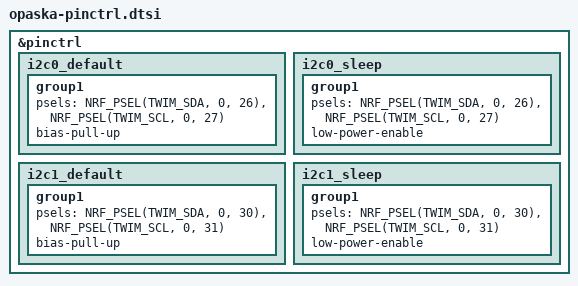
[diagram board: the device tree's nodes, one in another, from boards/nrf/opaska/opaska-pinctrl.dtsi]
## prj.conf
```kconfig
# Bluetooth (peripheral + GATT + notify)
CONFIG_BT=y
CONFIG_BT_PERIPHERAL=y
CONFIG_BT_DEVICE_NAME="nRF BPM"
CONFIG_BT_DEVICE_APPEARANCE=833
CONFIG_BT_MAX_PAIRED=1
CONFIG_BT_MAX_CONN=1
CONFIG_GPIO=y
CONFIG_GPIO_NRFX=y

CONFIG_BUILD_OUTPUT_HEX=y

# I2C (czujnik MAX30102)
CONFIG_I2C=y

# Wątek główny
CONFIG_MAIN_STACK_SIZE=4096
CONFIG_SYSTEM_WORKQUEUE_STACK_SIZE=2048

# Optymalizacja i debug
CONFIG_NEWLIB_LIBC=y
CONFIG_ASSERT=n
CONFIG_DEBUG_OPTIMIZATIONS=n
CONFIG_SPEED_OPTIMIZATIONS=y 
CONFIG_LOG=n
CONFIG_PRINTK=n
CONFIG_CONSOLE=n
CONFIG_UART_CONSOLE=n
CONFIG_SERIAL=n
CONFIG_BT_RX_STACK_SIZE=2048
CONFIG_BT_HCI_TX_STACK_SIZE=1024
CONFIG_HEAP_MEM_POOL_SIZE=4096

CONFIG_CLOCK_CONTROL=y
CONFIG_CLOCK_CONTROL_NRF=y

CONFIG_CLOCK_CONTROL_NRF_K32SRC_SYNTH=n
CONFIG_CLOCK_CONTROL_NRF_K32SRC_XTAL=y
CONFIG_CLOCK_CONTROL_NRF_K32SRC_RC=n

CONFIG_PM=y
CONFIG_PM_DEVICE=y
CONFIG_PM_DEVICE_RUNTIME=y
CONFIG_TICKLESS_KERNEL=y

# Preferowane parametry połączenia (jednostki: interval = 1.25 ms, timeout = 10 ms)
CONFIG_BT_PERIPHERAL_PREF_MIN_INT=160      
CONFIG_BT_PERIPHERAL_PREF_MAX_INT=320      

# W zależności od wersji Zephyra masz jedną z opcji:
CONFIG_BT_PERIPHERAL_PREF_LATENCY=4       
# albo:
# CONFIG_BT_PERIPHERAL_PREF_SLAVE_LATENCY=4

CONFIG_BT_PERIPHERAL_PREF_TIMEOUT=600     
```

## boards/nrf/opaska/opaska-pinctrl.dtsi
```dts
#include <zephyr/dt-bindings/pinctrl/nrf-pinctrl.h>

&pinctrl {
	i2c0_default: i2c0_default {
		group1 {
			psels = <NRF_PSEL(TWIM_SDA, 0, 26)>,
				<NRF_PSEL(TWIM_SCL, 0, 27)>;
			bias-pull-up;
		};
	};

	i2c0_sleep: i2c0_sleep {
		group1 {
			psels = <NRF_PSEL(TWIM_SDA, 0, 26)>,
				<NRF_PSEL(TWIM_SCL, 0, 27)>;
			low-power-enable;
		};
	};

	i2c1_default: i2c1_default {
		group1 {
			psels = <NRF_PSEL(TWIM_SDA, 0, 30)>,
				<NRF_PSEL(TWIM_SCL, 0, 31)>;
			bias-pull-up;
		};
	};

	i2c1_sleep: i2c1_sleep {
		group1 {
			psels = <NRF_PSEL(TWIM_SDA, 0, 30)>,
				<NRF_PSEL(TWIM_SCL, 0, 31)>;
			low-power-enable;
		};
	};
};
```

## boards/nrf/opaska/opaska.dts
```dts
/dts-v1/;

#include <nordic/nrf52840_qfaa.dtsi>
#include <nordic/nrf52840_partition.dtsi>
#include "opaska-pinctrl.dtsi"

&gpio0 { status = "okay"; };
&gpio1 { status = "okay"; };
&gpiote { status = "okay"; };

// &uart0 {
// 	status = "disabled";
// 	current-speed = <115200>;
// 	pinctrl-0 = <&uart0_default>;
// 	pinctrl-1 = <&uart0_sleep>;
// 	pinctrl-names = "default", "sleep";
// };

&i2c0 {
	status = "okay";
	pinctrl-0 = <&i2c0_default>;
	pinctrl-1 = <&i2c0_sleep>;
	pinctrl-names = "default", "sleep";
	clock-frequency = <I2C_BITRATE_STANDARD>;
};

&i2c1 {
	status = "okay";
	pinctrl-0 = <&i2c1_default>;
	pinctrl-1 = <&i2c1_sleep>;
	pinctrl-names = "default", "sleep";
	clock-frequency = <I2C_BITRATE_STANDARD>;
};

// &spi0 {
// 	status = "disabled";
// 	pinctrl-0 = <&spi0_default>;
// 	pinctrl-1 = <&spi0_sleep>;
// 	pinctrl-names = "default", "sleep";
// };
```

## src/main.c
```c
#include <zephyr/kernel.h>
#include <zephyr/drivers/i2c.h>
#include <zephyr/drivers/gpio.h>
#include <zephyr/device.h>
#include <zephyr/devicetree.h>
#include <stdint.h>
#include <stdbool.h>

#include "bpm.h"
#include "bpm_ble.h"
#include "wear_detect.h"

#define I2C_BPM_NODE   DT_NODELABEL(i2c0)
#define I2C_TEMP_NODE  DT_NODELABEL(i2c1)

#define BUZZER_PORT    DT_NODELABEL(gpio1)
#define BUZZER_PIN     15
#define TONE_HZ        4000

#define CALIBRATION_MS      15000
#define SEND_INTERVAL_MS     4000

#define BPM_MAX_VALID     200U
#define SPO2_MAX_VALID    100U

#define HR_ALARM_ON                 70U /* 70 bpm do testów*/
#define HR_ALARM_OFF                75U /* 75 bpm do testów*/
#define HR_ALARM_CONFIRM_SAMPLES    2U

#define ALARM_BEEP_PERIOD_MS        1000
#define ALARM_BEEP_TONE_MS          80

/* Timing */
#define MEAS_PERIOD_MS              40      /* 25 Hz */
#define WEAR_CHECK_ON_MS            1000
#define WEAR_CHECK_OFF_MS           200
#define OFF_BEEP_PERIOD_MS          1360

static const struct device *i2c_bpm;
static const struct device *i2c_temp;
static const struct device *buzzer_gpio;

/* generowanie dzwięku buzezera */
static void buzzer_tone(uint32_t freq_hz, uint32_t duration_ms)
{
    int64_t t_end = k_uptime_get() + (int64_t)duration_ms;
    uint32_t half_period_us = 1000000U / (freq_hz * 2U);

    while (k_uptime_get() < t_end) {
        gpio_pin_set(buzzer_gpio, BUZZER_PIN, 1);
        k_busy_wait(half_period_us);
        gpio_pin_set(buzzer_gpio, BUZZER_PIN, 0);
        k_busy_wait(half_period_us);
    }
    gpio_pin_set(buzzer_gpio, BUZZER_PIN, 0);
}
/* Ustawienie dźwięku dla opaski */
static void buzzer_band_off_pattern(void)
{
    buzzer_tone(TONE_HZ, 120);
    k_msleep(120);
    buzzer_tone(TONE_HZ, 120);
}
/* Ustawienie dźwięku dla alarmu opaski*/
static void buzzer_alarm_pattern(void)
{
    buzzer_tone(TONE_HZ, ALARM_BEEP_TONE_MS);
    k_msleep(ALARM_BEEP_TONE_MS);
    buzzer_tone(TONE_HZ, ALARM_BEEP_TONE_MS);
}
/* Sprawdzenie poprawności próbek */
static bool sample_valid(uint16_t hr, uint8_t s)
{
    if (hr == 0U || s == 0U) {
        return false;
    }
    if (hr > BPM_MAX_VALID) {
        return false;
    }
    if (s > SPO2_MAX_VALID) {
        return false;
    }
    return true;
}

static int64_t min_i64(int64_t a, int64_t b)
{
    return (a < b) ? a : b;
}

/* stan */
struct app_state {
    bool worn;
    bool calibrated;
    int64_t calib_end_ms;

    bool alarm_active;
    uint8_t low_confirm;
    uint8_t high_confirm;
    uint8_t last_alarm_sent;
};

static struct app_state st;
/* Ustawienie alarmu */
static void alarm_set(uint8_t on)
{
    on = on ? 1U : 0U;
    if (st.last_alarm_sent != on) {
        (void)ble_alarm_update(on);
        st.last_alarm_sent = on;
    }
}
/* Ustawienie dźwięku dla opaski */
static void on_band_put_on(int64_t now_ms)
{
    st.worn = true;
    st.calibrated = false;
    st.calib_end_ms = now_ms + (int64_t)CALIBRATION_MS;

    st.alarm_active = false;
    st.low_confirm = 0U;
    st.high_confirm = 0U;
    st.last_alarm_sent = 0U;

    alarm_set(0U);
    (void)ble_update(0U, 0U, true);
}
/* Ustawienie dźwięku dla opaski */
static void on_band_taken_off(void)
{
    st.worn = false;
    st.calibrated = false;

    st.alarm_active = false;
    st.low_confirm = 0U;
    st.high_confirm = 0U;
    st.last_alarm_sent = 0U;

    alarm_set(0U);
    (void)ble_update(0U, 0U, false);
}

int main(void)
{
    i2c_bpm  = DEVICE_DT_GET(I2C_BPM_NODE);
    i2c_temp = DEVICE_DT_GET(I2C_TEMP_NODE);
    buzzer_gpio = DEVICE_DT_GET(BUZZER_PORT);

    if (!device_is_ready(i2c_bpm) || !device_is_ready(i2c_temp)) {
        return 0;
    }
    if (!device_is_ready(buzzer_gpio)) {
        return 0;
    }
    if (gpio_pin_configure(buzzer_gpio, BUZZER_PIN, GPIO_OUTPUT_INACTIVE) != 0) {
        return 0;
    }

    bpm_init(i2c_bpm);
    (void)wear_detect_init(i2c_temp);
    ble_init();

    st.worn = false;
    st.calibrated = false;
    st.alarm_active = false;
    st.low_confirm = 0U;
    st.high_confirm = 0U;
    st.last_alarm_sent = 0U;
    st.calib_end_ms = 0;

    int64_t now = k_uptime_get();

    int64_t next_meas_ms       = now + (int64_t)MEAS_PERIOD_MS;
    int64_t next_wear_ms       = now;
    int64_t next_send_ms       = now + (int64_t)SEND_INTERVAL_MS;
    int64_t next_alarm_beep_ms = now + (int64_t)ALARM_BEEP_PERIOD_MS;
    int64_t next_off_beep_ms   = now;

    /* Wykryj czy założona */
    bool worn0 = wear_detect(i2c_temp);
    now = k_uptime_get();
    if (worn0) {
        on_band_put_on(now);
        next_send_ms = st.calib_end_ms;
        next_wear_ms = now + (int64_t)WEAR_CHECK_ON_MS;
    } else {
        on_band_taken_off();
        next_wear_ms = now + (int64_t)WEAR_CHECK_OFF_MS;
    }

    while (1) {
        now = k_uptime_get();

        /* Wear detect */
        if (now >= next_wear_ms) {
            bool w = wear_detect(i2c_temp);

            if (w && !st.worn) {
                on_band_put_on(now);
                next_send_ms = st.calib_end_ms;
                next_meas_ms = now + (int64_t)MEAS_PERIOD_MS;
                next_wear_ms = now + (int64_t)WEAR_CHECK_ON_MS;
            } else if (!w && st.worn) {
                on_band_taken_off();
                next_off_beep_ms = now;
                next_wear_ms = now + (int64_t)WEAR_CHECK_OFF_MS;
            } else {
                next_wear_ms = now + (int64_t)(st.worn ? WEAR_CHECK_ON_MS : WEAR_CHECK_OFF_MS);
            }
        }

        if (st.worn) {
            /* Kalibracja */
            if (!st.calibrated && now >= st.calib_end_ms) {
                st.calibrated = true;
                st.alarm_active = false;
                st.low_confirm = 0U;
                st.high_confirm = 0U;
                alarm_set(0U);
                next_send_ms = now;
            }

            /* nadrabiaj brakujące ticki  */
            int catchup = 0;
            while (now >= next_meas_ms && catchup < 5) {
                bpm_process(i2c_bpm);
                next_meas_ms += (int64_t)MEAS_PERIOD_MS;
                catchup++;
                now = k_uptime_get();
            }
            if (catchup >= 5) {
                /* jak było duże opóźnienie, zresync do "teraz" */
                next_meas_ms = now + (int64_t)MEAS_PERIOD_MS;
            }

            /* Logika alarmu po aktualizacji bpm/spo2 */
            if (st.calibrated && sample_valid(bpm, spo2)) {
                if (!st.alarm_active) {
                    if (bpm < HR_ALARM_ON) {
                        if (st.low_confirm < 255U) {
                            st.low_confirm++;
                        }
                        if (st.low_confirm >= HR_ALARM_CONFIRM_SAMPLES) {
                            st.alarm_active = true;
                            st.high_confirm = 0U;
                            alarm_set(1U);
                            next_alarm_beep_ms = now;
                        }
                    } else {
                        st.low_confirm = 0U;
                    }
                } else {
                    if (bpm > HR_ALARM_OFF) {
                        if (st.high_confirm < 255U) {
                            st.high_confirm++;
                        }
                        if (st.high_confirm >= HR_ALARM_CONFIRM_SAMPLES) {
                            st.alarm_active = false;
                            st.low_confirm = 0U;
                            alarm_set(0U);
                        }
                    } else {
                        st.high_confirm = 0U;
                    }
                }
            }

            /* Alarm beep */
            if (st.calibrated && st.alarm_active && now >= next_alarm_beep_ms) {
                buzzer_alarm_pattern();
                next_alarm_beep_ms += (int64_t)ALARM_BEEP_PERIOD_MS;
                while (next_alarm_beep_ms <= now) {
                    next_alarm_beep_ms += (int64_t)ALARM_BEEP_PERIOD_MS;
                }
            }

            /* BLE wysyłka */
            if (st.calibrated && now >= next_send_ms) {
                if (sample_valid(bpm, spo2)) {
                    (void)ble_update(bpm, spo2, true);
                } else {
                    (void)ble_update(0U, 0U, true);
                }

                next_send_ms += (int64_t)SEND_INTERVAL_MS;
                while (next_send_ms <= now) {
                    next_send_ms += (int64_t)SEND_INTERVAL_MS;
                }
            }
        } else {
            /* Zdjęta */
            if (now >= next_off_beep_ms) {
                buzzer_band_off_pattern();
                next_off_beep_ms = now + (int64_t)OFF_BEEP_PERIOD_MS;
            }
        }

        /* Sen do najbli ższego deadline */
        int64_t next_deadline = now + 50;
        next_deadline = min_i64(next_deadline, next_wear_ms);

        if (st.worn) {
            next_deadline = min_i64(next_deadline, next_meas_ms);
            if (st.calibrated) {
                next_deadline = min_i64(next_deadline, next_send_ms);
                if (st.alarm_active) {
                    next_deadline = min_i64(next_deadline, next_alarm_beep_ms);
                }
            }
        } else {
            next_deadline = min_i64(next_deadline, next_off_beep_ms);
        }

        int64_t sleep_ms = next_deadline - k_uptime_get();
        if (sleep_ms < 0) {
            sleep_ms = 0;
        }
        if (sleep_ms > 100) {
            sleep_ms = 100;
        }

        k_msleep((uint32_t)sleep_ms);
    }

    return 0;
}
```

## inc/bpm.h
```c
#ifndef BPM_H_
#define BPM_H_

#include <zephyr/device.h>
#include <stdint.h>

/* Wyniki ostatniego poprawnego pomiaru */
extern uint16_t bpm;  
extern uint8_t  spo2; 

void bpm_init(const struct device *i2c_dev);
void bpm_process(const struct device *i2c_dev);
void bpm_reset_state(void);

#endif 
```

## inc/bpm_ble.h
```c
#pragma once
#include <stdint.h>
#include <stdbool.h>
void ble_init(void);

int ble_update(uint16_t bpm, uint8_t spo2, bool worn);

/* 0 = brak alarmu, 1 = alarm aktywny */
int ble_alarm_update(uint8_t alarm);
```

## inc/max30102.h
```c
#ifndef MAX30102_H_
#define MAX30102_H_

#include <zephyr/device.h>
#include <stdint.h>
#include <stdbool.h>

#define MAX30102_ADDRESS  0x57 // I2C Address for MAX30102

#define MAX30102_INT_STATUS_1        0x00
#define MAX30102_INT_STATUS_2        0x01
#define MAX30102_INT_ENABLE_1        0x02
#define MAX30102_INT_ENABLE_2        0x03
#define MAX30102_FIFO_WRITE_PTR      0x04
#define MAX30102_OVERFLOW_COUNT      0x05
#define MAX30102_FIFO_READ_PTR       0x06
#define MAX30102_REG_FIFO_DATA       0x07
#define MAX30102_FIFO_CONFIG         0x08
#define MAX30102_MODE_CONFIG         0x09
#define MAX30102_SPO2_CONFIG         0x0A
#define MAX30102_LED1_PULSE_AMP      0x0C
#define MAX30102_LED2_PULSE_AMP      0x0D
#define MAX30102_PARTID              0xFF
#define MAX30102_RESET               0x40

/* Deklaracje funkcji dostępnych globalnie */
int  MAX30102_check(const struct device *dev_i2c);
int  MAX30102_reset(const struct device *dev_i2c);
int  MAX30102_clear(const struct device *dev_i2c);
int  MAX30102_config(const struct device *dev_i2c);
bool MAX30102_read_fifo(const struct device *dev_i2c, uint32_t *pun_red_led, uint32_t *pun_ir_led);
bool MAX30102_read_reg(const struct device *dev_i2c, uint8_t uch_addr, uint8_t *puch_data);
bool MAX30102_set_shutdown(const struct device *i2c, bool en);
void max30102_enable(const struct device *dev, bool enable);
void max30102_read_samples(const struct device *dev);
uint8_t max30102_calculate_bpm(void);

#endif 
```

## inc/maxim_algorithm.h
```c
#ifndef MAXIM_ALGORITHM_H_
#define MAXIM_ALGORITHM_H_

#include <stdint.h>

void maxim_heart_rate_and_oxygen_saturation(
    uint32_t *ir_buf,
    int32_t buf_len,
    uint32_t *red_buf,
    int32_t *spo2,
    int8_t *spo2_valid,
    int32_t *heart_rate,
    int8_t *hr_valid);

#endif /* MAXIM_ALGORITHM_H_ */
```

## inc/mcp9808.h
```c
#pragma once
#include <zephyr/device.h>
#include <stdbool.h>
// Odczyt temperatury z MCP9808
bool mcp9808_read_temp(const struct device *i2c, float *out_temp_c);
```

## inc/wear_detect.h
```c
#pragma once
#include <zephyr/device.h>
#include <stdbool.h>

// Inicjalizacja czujnika temperatury
bool wear_detect_init(const struct device *i2c_temp);
// Wykrywanie czy urządzenie jest założone
bool wear_detect(const struct device *i2c_temp);
```

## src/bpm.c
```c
#include "bpm.h"
#include "max30102.h"
#include "maxim_algorithm.h"
#include <zephyr/kernel.h>
#include <stdint.h>
#include <stdbool.h>

#define MAXIM_BUF_LEN   100     /* 4 sekundy przy FreqS=25 w algorytmie */
#define FILTER_SIZE     5

static int bpm_buffer[FILTER_SIZE];
static int bpm_index = 0;
static bool buffer_filled = false;

static uint32_t ir_buf[MAXIM_BUF_LEN];
static uint32_t red_buf[MAXIM_BUF_LEN];
static int buf_idx = 0;


uint16_t bpm = 0;
uint8_t  spo2 = 0;

/* Ostatnie poprawne wyniki */
static uint16_t last_bpm = 0;
static uint8_t  last_spo2 = 0;

static int bpm_get_filtered(int new_bpm)
{
    bpm_buffer[bpm_index++] = new_bpm;
    if (bpm_index >= FILTER_SIZE) {
        bpm_index = 0;
        buffer_filled = true;
    }

    int count = buffer_filled ? FILTER_SIZE : bpm_index;
    int sum = 0;
    for (int i = 0; i < count; i++) {
        sum += bpm_buffer[i];
    }
    return (count > 0) ? (sum / count) : new_bpm;
}
    /* Inicjalizacja modułu BPM */
void bpm_init(const struct device *i2c_dev)
{
    MAX30102_check(i2c_dev);
    MAX30102_reset(i2c_dev);
    k_msleep(100);

    MAX30102_config(i2c_dev);
    k_msleep(100);

    buf_idx = 0;
    bpm = 0;
    spo2 = 0;
    last_bpm = 0;
    last_spo2 = 0;
    bpm_index = 0;
    buffer_filled = false;
}
/* Przetwarzanie danych BPM */
void bpm_process(const struct device *i2c_dev)
{
    uint32_t ir_raw = 0, red_raw = 0;

    if (!MAX30102_read_fifo(i2c_dev, &red_raw, &ir_raw)) {
        return;
    }

    ir_buf[buf_idx]  = ir_raw;
    red_buf[buf_idx] = red_raw;
    buf_idx++;

    if (buf_idx >= MAXIM_BUF_LEN) {
        int32_t spo2_calc = 0, hr_calc = 0;
        int8_t spo2_valid = 0, hr_valid = 0;

        maxim_heart_rate_and_oxygen_saturation(
            ir_buf, MAXIM_BUF_LEN, red_buf,
            &spo2_calc, &spo2_valid, &hr_calc, &hr_valid);

        if (hr_valid) {
            int32_t hr = hr_calc;
            if (hr < 0) { hr = 0; }
            if (hr > 250) { hr = 250; }
            last_bpm = (uint16_t)bpm_get_filtered((int)hr);
        }

        if (spo2_valid) {
            int32_t s = spo2_calc;
            if (s < 0) { s = 0; }
            if (s > 100) { s = 100; }
            last_spo2 = (uint8_t)s;
        }

        bpm = last_bpm;
        spo2 = last_spo2;

        buf_idx = 0;
    }
}
/* Resetowanie stanu modułu BPM */
void bpm_reset_state(void)
{
    /* reset filtra */
    for (int i = 0; i < FILTER_SIZE; i++) {
        bpm_buffer[i] = 0;
    }
    bpm_index = 0;
    buffer_filled = false;

    /* reset buforów próbek */
    for (int i = 0; i < MAXIM_BUF_LEN; i++) {
        ir_buf[i] = 0;
        red_buf[i] = 0;
    }
    buf_idx = 0;

    /* reset wyników */
    bpm = 0;
    spo2 = 0;
    last_bpm = 0;
    last_spo2 = 0;
}
```

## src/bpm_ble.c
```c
#include <zephyr/kernel.h>
#include <zephyr/sys/byteorder.h>
#include <zephyr/sys/util.h>
#include <errno.h>
#include <stdbool.h>
#include <stdint.h>

#include <zephyr/bluetooth/bluetooth.h>
#include <zephyr/bluetooth/conn.h>
#include <zephyr/bluetooth/gatt.h>
#include <zephyr/bluetooth/hci.h>

#include "bpm_ble.h"

/* HR (0x180D/0x2A37) */
static struct bt_uuid_16 hrs_uuid = BT_UUID_INIT_16(0x180D);
static struct bt_uuid_16 hrm_uuid = BT_UUID_INIT_16(0x2A37);

static bool hrm_notify_enabled;
static uint8_t hrm_payload[2];

static void hrm_ccc_cfg_changed(const struct bt_gatt_attr *attr, uint16_t value)
{
    ARG_UNUSED(attr);
    hrm_notify_enabled = (value == BT_GATT_CCC_NOTIFY);
}

BT_GATT_SERVICE_DEFINE(hrs_svc,
    BT_GATT_PRIMARY_SERVICE(&hrs_uuid.uuid),
    BT_GATT_CHARACTERISTIC(&hrm_uuid.uuid,
        BT_GATT_CHRC_NOTIFY,
        BT_GATT_PERM_NONE,
        NULL, NULL, hrm_payload),
    BT_GATT_CCC(hrm_ccc_cfg_changed, BT_GATT_PERM_READ | BT_GATT_PERM_WRITE)
);

static int hrs_notify(struct bt_conn *conn, uint16_t bpm, bool worn)
{
    if (!conn || !hrm_notify_enabled) {
        return 0;
    }

    hrm_payload[0] = 0x00;
    hrm_payload[0] |= (1U << 1);
    if (worn) {
        hrm_payload[0] |= (1U << 2);
    }
    hrm_payload[1] = (uint8_t)MIN(bpm, 255);

    return bt_gatt_notify(conn, &hrs_svc.attrs[2], hrm_payload, sizeof(hrm_payload));
}

/* PLX (0x1822/0x2A5F + 0x2A60) */
static struct bt_uuid_16 plx_svc_uuid  = BT_UUID_INIT_16(0x1822);
static struct bt_uuid_16 plx_cont_uuid = BT_UUID_INIT_16(0x2A5F);
static struct bt_uuid_16 plx_feat_uuid = BT_UUID_INIT_16(0x2A60);

static bool plx_notify_enabled;
static uint8_t plx_payload[5];
static uint16_t plx_features_le = 0x0000;

static void plx_ccc_cfg_changed(const struct bt_gatt_attr *attr, uint16_t value)
{
    ARG_UNUSED(attr);
    plx_notify_enabled = (value == BT_GATT_CCC_NOTIFY);
}

static ssize_t read_plx_features(struct bt_conn *conn,
                                 const struct bt_gatt_attr *attr,
                                 void *buf, uint16_t len, uint16_t offset)
{
    ARG_UNUSED(attr);
    return bt_gatt_attr_read(conn, attr, buf, len, offset,
                             &plx_features_le, sizeof(plx_features_le));
}

static uint16_t sfloat_encode_int(int16_t mantissa, int8_t exponent)
{
    uint16_t m = (uint16_t)mantissa & 0x0FFF;
    uint16_t e = ((uint16_t)exponent & 0x000F) << 12;
    return (uint16_t)(e | m);
}

BT_GATT_SERVICE_DEFINE(plx_svc,
    BT_GATT_PRIMARY_SERVICE(&plx_svc_uuid.uuid),

    BT_GATT_CHARACTERISTIC(&plx_cont_uuid.uuid,
        BT_GATT_CHRC_NOTIFY,
        BT_GATT_PERM_NONE,
        NULL, NULL, plx_payload),
    BT_GATT_CCC(plx_ccc_cfg_changed, BT_GATT_PERM_READ | BT_GATT_PERM_WRITE),

    BT_GATT_CHARACTERISTIC(&plx_feat_uuid.uuid,
        BT_GATT_CHRC_READ,
        BT_GATT_PERM_READ,
        read_plx_features, NULL, &plx_features_le)
);

static int plx_notify(struct bt_conn *conn, uint8_t spo2_percent, uint16_t pulse_rate_bpm)
{
    if (!conn || !plx_notify_enabled) {
        return 0;
    }

    plx_payload[0] = 0x00;

    uint16_t spo2_sf = sfloat_encode_int((int16_t)spo2_percent, 0);
    uint16_t pr_sf   = sfloat_encode_int((int16_t)MIN(pulse_rate_bpm, 300), 0);

    sys_put_le16(spo2_sf, &plx_payload[1]);
    sys_put_le16(pr_sf,   &plx_payload[3]);

    return bt_gatt_notify(conn, &plx_svc.attrs[2], plx_payload, sizeof(plx_payload));
}

/* Custom */
#define BT_UUID_BPM_SPO2_SVC_VAL \
    BT_UUID_128_ENCODE(0x12345678, 0x1234, 0x5678, 0x1234, 0x56789abcdef0)

#define BT_UUID_SPO2_CHAR_VAL \
    BT_UUID_128_ENCODE(0x1234567a, 0x1234, 0x5678, 0x1234, 0x56789abcdef0)

#define BT_UUID_ALARM_CHAR_VAL \
    BT_UUID_128_ENCODE(0x1234567b, 0x1234, 0x5678, 0x1234, 0x56789abcdef0)

static struct bt_uuid_128 custom_svc_uuid = BT_UUID_INIT_128(BT_UUID_BPM_SPO2_SVC_VAL);
static struct bt_uuid_128 spo2_uuid       = BT_UUID_INIT_128(BT_UUID_SPO2_CHAR_VAL);
static struct bt_uuid_128 alarm_uuid      = BT_UUID_INIT_128(BT_UUID_ALARM_CHAR_VAL);

static uint8_t g_spo2;
static uint8_t g_alarm;

static bool spo2_notify_enabled;
static bool alarm_notify_enabled;

static void spo2_ccc_cfg_changed(const struct bt_gatt_attr *attr, uint16_t value)
{
    ARG_UNUSED(attr);
    spo2_notify_enabled = (value == BT_GATT_CCC_NOTIFY);
}

static void alarm_ccc_cfg_changed(const struct bt_gatt_attr *attr, uint16_t value)
{
    ARG_UNUSED(attr);
    alarm_notify_enabled = (value == BT_GATT_CCC_NOTIFY);
}

BT_GATT_SERVICE_DEFINE(custom_svc,
    BT_GATT_PRIMARY_SERVICE(&custom_svc_uuid),

    BT_GATT_CHARACTERISTIC(&spo2_uuid.uuid,
        BT_GATT_CHRC_NOTIFY,
        BT_GATT_PERM_NONE,
        NULL, NULL, &g_spo2),
    BT_GATT_CCC(spo2_ccc_cfg_changed, BT_GATT_PERM_READ | BT_GATT_PERM_WRITE),

    BT_GATT_CHARACTERISTIC(&alarm_uuid.uuid,
        BT_GATT_CHRC_NOTIFY,
        BT_GATT_PERM_NONE,
        NULL, NULL, &g_alarm),
    BT_GATT_CCC(alarm_ccc_cfg_changed, BT_GATT_PERM_READ | BT_GATT_PERM_WRITE)
);

/* Adv + conn */
static struct bt_conn *current_conn;

static const struct bt_data ad[] = {
    BT_DATA_BYTES(BT_DATA_FLAGS, (BT_LE_AD_GENERAL | BT_LE_AD_NO_BREDR)),
    BT_DATA_BYTES(BT_DATA_UUID16_ALL, 0x0D, 0x18, 0x22, 0x18),
    BT_DATA_BYTES(BT_DATA_UUID128_ALL, BT_UUID_BPM_SPO2_SVC_VAL),
};

static const struct bt_data sd[] = {
    BT_DATA(BT_DATA_NAME_COMPLETE, CONFIG_BT_DEVICE_NAME,
            sizeof(CONFIG_BT_DEVICE_NAME) - 1),
};

static const struct bt_le_adv_param adv_param = {
    .id = BT_ID_DEFAULT,
    .options = BT_LE_ADV_OPT_CONN,
    .interval_min = 0x0640,
    .interval_max = 0x06A4,
    .peer = NULL,
};

static int start_advertising(void)
{
    int err = bt_le_adv_start(&adv_param, ad, ARRAY_SIZE(ad), sd, ARRAY_SIZE(sd));
    if (err == -EALREADY) {
        return 0;
    }
    return err;
}

static void adv_work_handler(struct k_work *work);
K_WORK_DELAYABLE_DEFINE(adv_work, adv_work_handler);

static void adv_work_handler(struct k_work *work)
{
    ARG_UNUSED(work);
    (void)start_advertising();
}

static void connected(struct bt_conn *conn, uint8_t err)
{
    if (err) {
        return;
    }

    if (current_conn) {
        bt_conn_unref(current_conn);
    }
    current_conn = bt_conn_ref(conn);
}

static void disconnected(struct bt_conn *conn, uint8_t reason)
{
    ARG_UNUSED(conn);
    ARG_UNUSED(reason);

    hrm_notify_enabled = false;
    plx_notify_enabled = false;
    spo2_notify_enabled = false;
    alarm_notify_enabled = false;

    if (current_conn) {
        bt_conn_unref(current_conn);
        current_conn = NULL;
    }

    (void)k_work_schedule(&adv_work, K_MSEC(200));
}

BT_CONN_CB_DEFINE(conn_cb) = {
    .connected = connected,
    .disconnected = disconnected,
};

void ble_init(void)
{
    int err = bt_enable(NULL);
    if (err) {
        return;
    }

    g_spo2 = 0;
    g_alarm = 0;

    plx_features_le = sys_cpu_to_le16(plx_features_le);

    (void)start_advertising();
}

int ble_update(uint16_t bpm, uint8_t spo2, bool worn)
{
    int err;

    g_spo2 = spo2;

    if (!current_conn) {
        return 0;
    }

    err = hrs_notify(current_conn, bpm, worn);
    if (err == -ENOMEM || err == -EAGAIN) {
        err = 0;
    }
    if (err) {
        return err;
    }

    err = plx_notify(current_conn, spo2, bpm);
    if (err == -ENOMEM || err == -EAGAIN) {
        err = 0;
    }
    if (err) {
        return err;
    }

    if (spo2_notify_enabled) {
        err = bt_gatt_notify_uuid(current_conn, &spo2_uuid.uuid,
                                  custom_svc.attrs, &g_spo2, sizeof(g_spo2));
        if (err == -ENOMEM || err == -EAGAIN) {
            err = 0;
        }
        if (err) {
            return err;
        }
    }

    return 0;
}

int ble_alarm_update(uint8_t alarm)
{
    int err;

    alarm = alarm ? 1U : 0U;
    if (g_alarm == alarm) {
        return 0;
    }

    g_alarm = alarm;

    if (!current_conn || !alarm_notify_enabled) {
        return 0;
    }

    err = bt_gatt_notify_uuid(current_conn, &alarm_uuid.uuid,
                              custom_svc.attrs, &g_alarm, sizeof(g_alarm));
    if (err == -ENOMEM || err == -EAGAIN) {
        return 0;
    }

    return err;
}
```

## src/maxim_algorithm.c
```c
/** \file maxim_algorithm.c ***************************************************
*
* Project: MAXREFDES117# (adaptacja)
* Filename: maxim_algorithm.c
* Description: This module calculates the heart rate/SpO2 level
*              (adapted for Zephyr / nRF52 environment)
*
* --------------------------------------------------------------------
*
* This code follows the following naming conventions:
*
* char              ch_pmod_value
* char (array)      s_pmod_s_string[16]
* float             f_pmod_value
* int32_t           n_pmod_value
* int32_t (array)   an_pmod_value[16]
* int16_t           w_pmod_value
* int16_t (array)   aw_pmod_value[16]
* uint16_t          uw_pmod_value
* uint16_t (array)  auw_pmod_value[16]
* uint8_t           uch_pmod_value
* uint8_t (array)   auch_pmod_buffer[16]
* uint32_t          un_pmod_value
* int32_t *         pn_pmod_value
*
* ------------------------------------------------------------------------- */
/*******************************************************************************
* Copyright (C) 2016 Maxim Integrated Products, Inc., All Rights Reserved.
*
* Permission is hereby granted, free of charge, to any person obtaining a
* copy of this software and associated documentation files (the "Software"),
* to deal in the Software without restriction, including without limitation
* the rights to use, copy, modify, merge, publish, distribute, sublicense,
* and/or sell copies of the Software, and to permit persons to whom the
* Software is furnished to do so, subject to the following conditions:
*
* The above copyright notice and this permission notice shall be included
* in all copies or substantial portions of the Software.
*
* THE SOFTWARE IS PROVIDED "AS IS", WITHOUT WARRANTY OF ANY KIND, EXPRESS
* OR IMPLIED, INCLUDING BUT NOT LIMITED TO THE WARRANTIES OF
* MERCHANTABILITY, FITNESS FOR A PARTICULAR PURPOSE AND NONINFRINGEMENT.
* IN NO EVENT SHALL MAXIM INTEGRATED BE LIABLE FOR ANY CLAIM, DAMAGES
* OR OTHER LIABILITY, WHETHER IN AN ACTION OF CONTRACT, TORT OR OTHERWISE,
* ARISING FROM, OUT OF OR IN CONNECTION WITH THE SOFTWARE OR THE USE OR
* OTHER DEALINGS IN THE SOFTWARE.
*
* Except as contained in this notice, the name of Maxim Integrated
* Products, Inc. shall not be used except as stated in the Maxim Integrated
* Products, Inc. Branding Policy.
*
* The mere transfer of this software does not imply any licenses
* of trade secrets, proprietary technology, copyrights, patents,
* trademarks, maskwork rights, or any other form of intellectual
* property whatsoever. Maxim Integrated Products, Inc. retains all
* ownership rights.
*******************************************************************************
*/

#include "maxim_algorithm.h"
#include <stdint.h>

#define FreqS 25
#define BUFFER_SIZE (FreqS * 4)   /* 100 próbek */
#define MA4_SIZE 4
#define min(x,y) ((x) < (y) ? (x) : (y))

/* Ustawienia pod nadgarstek */
#define HR_MAX_BPM       180      /* do min_dist w 1. przebiegu (bezpieczne) */
#define MIN_DIST_FRAC_N  6        /* 2. przebieg: min_dist ~= 0.7 * okresu */
#define MIN_DIST_FRAC_D  10

static const uint8_t uch_spo2_table[184] = {
    95,95,95,96,96,96,97,97,97,97,97,98,98,98,98,98,99,99,99,99,
    99,99,99,99,100,100,100,100,100,100,100,100,100,100,100,100,100,100,100,100,
    100,100,100,100,99,99,99,99,99,99,99,99,98,98,98,98,98,98,97,97,
    97,97,96,96,96,96,95,95,95,94,94,94,93,93,93,92,92,92,91,91,
    90,90,89,89,89,88,88,87,87,86,86,85,85,84,84,83,82,82,81,81,
    80,80,79,78,78,77,76,76,75,74,74,73,72,72,71,70,69,69,68,67,
    66,66,65,64,63,62,62,61,60,59,58,57,56,56,55,54,53,52,51,50,
    49,48,47,46,45,44,43,42,41,40,39,38,37,36,35,34,33,31,30,29,
    28,27,26,25,23,22,21,20,19,17,16,15,14,12,11,10,9,7,6,5,
    3,2,1
};

static int32_t an_x[BUFFER_SIZE]; /* IR */
static int32_t an_y[BUFFER_SIZE]; /* RED */

/**
* \brief        Sort array
* \par          Details
*               Sort array in ascending order (insertion sort algorithm)
*
* \retval       None
*/
static void maxim_sort_ascend(int32_t *x, int32_t n)
{
    for (int i = 1; i < n; i++) {
        int32_t t = x[i], j = i;
        while (j > 0 && t < x[j - 1]) {
            x[j] = x[j - 1];
            j--;
        }
        x[j] = t;
    }
}

/**
* \brief        Sort indices
* \par          Details
*               Sort indices according to descending order (insertion sort algorithm)
*
* \retval       None
*/
static void maxim_sort_indices_descend(int32_t *x, int32_t *idx, int32_t n)
{
    for (int i = 1; i < n; i++) {
        int32_t t = idx[i], j = i;
        while (j > 0 && x[t] > x[idx[j - 1]]) {
            idx[j] = idx[j - 1];
            j--;
        }
        idx[j] = t;
    }
}

/**
* \brief        Find peaks above n_min_height
* \par          Details
*               Find all peaks above MIN_HEIGHT
*
* \retval       None
*/
static void maxim_peaks_above_min_height(int32_t *locs, int32_t *npks,
                                         int32_t *x, int32_t n, int32_t min_h)
{
    *npks = 0;
    int32_t i = 1;

    while (i < n - 1) {
        if (x[i] > min_h && x[i] > x[i - 1]) {
            int32_t w = 1;
            while ((i + w) < n && x[i] == x[i + w]) {
                w++;
            }
            /* guard: i+w może == n */
            if ((i + w) < n && x[i] > x[i + w] && *npks < 15) {
                locs[(*npks)++] = i;
                i += (w + 1);
            } else {
                i += w;
            }
        } else {
            i++;
        }
    }
}

/**
* \brief        Remove peaks
* \par          Details
*               Remove peaks separated by less than MIN_DISTANCE
*
* \retval       None
*/
static void maxim_remove_close_peaks(int32_t *locs, int32_t *npks,
                                     int32_t *x, int32_t min_dist)
{
    int old_npks;
    maxim_sort_indices_descend(x, locs, *npks);

    for (int i = -1; i < *npks; i++) {
        old_npks = *npks;
        *npks = i + 1;

        for (int j = i + 1; j < old_npks; j++) {
            int d = locs[j] - (i == -1 ? -1 : locs[i]);
            if (d > min_dist || d < -min_dist) {
                locs[(*npks)++] = locs[j];
            }
        }
    }
    maxim_sort_ascend(locs, *npks);
}

/**
* \brief        Find peaks
* \par          Details
*               Find at most MAX_NUM peaks above MIN_HEIGHT separated by at least MIN_DISTANCE
*
* \retval       None
*/
static void maxim_find_peaks(int32_t *locs, int32_t *npks, int32_t *x, int32_t n,
                             int32_t min_h, int32_t min_dist, int32_t max_num)
{
    maxim_peaks_above_min_height(locs, npks, x, n, min_h);
    maxim_remove_close_peaks(locs, npks, x, min_dist);
    *npks = min(*npks, max_num);
}

/**
* \brief        Compute heart rate from median peak intervals
* \par          Details
*               Uses median of successive peak-to-peak distances (in samples),
*               then converts to BPM using sampling rate FreqS.
*
* \retval       Heart rate in BPM, or -999 on failure
*/
static int32_t hr_from_median_intervals(const int32_t *locs, int32_t npks)
{
    if (npks < 2) {
        return -999;
    }

    int32_t d[14];
    int32_t m = 0;

    for (int32_t k = 1; k < npks; k++) {
        d[m++] = (locs[k] - locs[k - 1]);
        if (m >= (int32_t)(sizeof(d) / sizeof(d[0]))) {
            break;
        }
    }

    if (m < 1) {
        return -999;
    }

    maxim_sort_ascend(d, m);
    int32_t med = (m % 2) ? d[m / 2] : (d[m / 2 - 1] + d[m / 2]) / 2;
    if (med <= 0) {
        return -999;
    }

    return (int32_t)((FreqS * 60) / med);
}

/**
* \brief        Calculate the heart rate and SpO2 level
* \par          Details
*               By detecting peaks (valleys after inversion) of PPG cycle and corresponding AC/DC
*               of red/infra-red signal, the ratio for the SPO2 is computed and mapped through a LUT.
*
* \param[in]    *ir_buf               - IR sensor data buffer
* \param[in]    n                    - IR/RED buffer length (expected BUFFER_SIZE)
* \param[in]    *red_buf              - Red sensor data buffer
* \param[out]   *spo2                 - Calculated SpO2 value
* \param[out]   *spo2_valid           - 1 if the calculated SpO2 value is valid
* \param[out]   *hr                   - Calculated heart rate value
* \param[out]   *hr_valid             - 1 if the calculated heart rate value is valid
*
* \retval       None
*/
void maxim_heart_rate_and_oxygen_saturation(
    uint32_t *ir_buf, int32_t n, uint32_t *red_buf,
    int32_t *spo2, int8_t *spo2_valid, int32_t *hr, int8_t *hr_valid)
{
    /* Zakładamy, że i tak wołasz z n==BUFFER_SIZE */
    (void)n;

    /* --- IR mean --- */
    uint32_t ir_mean = 0;
    for (int k = 0; k < BUFFER_SIZE; k++) {
        ir_mean += ir_buf[k];
    }
    ir_mean /= BUFFER_SIZE;

    /* remove DC and invert signal so that we can use peak detector as valley detector */
    for (int k = 0; k < BUFFER_SIZE; k++) {
        an_x[k] = -(int32_t)(ir_buf[k] - ir_mean);
    }

    /* 4 pt Moving Average */
    for (int k = 0; k < BUFFER_SIZE - MA4_SIZE; k++) {
        an_x[k] = (an_x[k] + an_x[k + 1] + an_x[k + 2] + an_x[k + 3]) / 4;
    }

    /* calculate threshold */
    int32_t th = 0;
    for (int k = 0; k < BUFFER_SIZE; k++) {
        th += an_x[k];
    }
    th /= BUFFER_SIZE;

    if (th < 30) th = 30;
    if (th > 60) th = 60;

    int32_t valley_locs[15] = {0};
    int32_t npks = 0;

    /* --- Pass 1: loose min_dist (based on HR_MAX_BPM) --- */
    int32_t min_dist1 = (FreqS * 60) / HR_MAX_BPM;
    if (min_dist1 < 4) min_dist1 = 4;

    maxim_find_peaks(valley_locs, &npks, an_x, BUFFER_SIZE, th, min_dist1, 15);

    int32_t hr1 = -999;
    if (npks >= 2) {
        hr1 = hr_from_median_intervals(valley_locs, npks);
    }

    /* --- Pass 2: tighten min_dist based on estimated period --- */
    if (hr1 > 0) {
        int32_t period = (FreqS * 60) / hr1;
        int32_t min_dist2 = (period * MIN_DIST_FRAC_N) / MIN_DIST_FRAC_D;
        if (min_dist2 < min_dist1) min_dist2 = min_dist1;

        maxim_find_peaks(valley_locs, &npks, an_x, BUFFER_SIZE, th, min_dist2, 15);
    }

    /* HR final (median intervals) */
    if (npks >= 2) {
        *hr = hr_from_median_intervals(valley_locs, npks);
        *hr_valid = (*hr > 0) ? 1 : 0;
        if (!(*hr_valid)) {
            *hr = -999;
        }
    } else {
        *hr = -999;
        *hr_valid = 0;
    }

    /* --- SpO2 calculation (ratio-of-ratios + LUT) --- */
    for (int k = 0; k < BUFFER_SIZE; k++) {
        an_x[k] = (int32_t)ir_buf[k];
        an_y[k] = (int32_t)red_buf[k];
    }

    int32_t ratio[5] = {0};
    int32_t ratio_cnt = 0;

    for (int k = 0; k < npks - 1 && ratio_cnt < 5; k++) {
        if (valley_locs[k + 1] - valley_locs[k] <= 3) {
            continue;
        }

        int32_t x_dc_max = -16777216, y_dc_max = -16777216;
        int32_t x_dc_max_i = 0,       y_dc_max_i = 0;

        for (int i = valley_locs[k]; i < valley_locs[k + 1]; i++) {
            if (an_x[i] > x_dc_max) { x_dc_max = an_x[i]; x_dc_max_i = i; }
            if (an_y[i] > y_dc_max) { y_dc_max = an_y[i]; y_dc_max_i = i; }
        }

        int32_t y_ac = (an_y[valley_locs[k + 1]] - an_y[valley_locs[k]]) * (y_dc_max_i - valley_locs[k]);
        y_ac = an_y[valley_locs[k]] + y_ac / (valley_locs[k + 1] - valley_locs[k]);
        y_ac = an_y[y_dc_max_i] - y_ac;

        int32_t x_ac = (an_x[valley_locs[k + 1]] - an_x[valley_locs[k]]) * (x_dc_max_i - valley_locs[k]);
        x_ac = an_x[valley_locs[k]] + x_ac / (valley_locs[k + 1] - valley_locs[k]);
        /* BUGFIX: correct index for IR AC */
        x_ac = an_x[x_dc_max_i] - x_ac;

        int32_t nume  = (y_ac * x_dc_max) >> 7;
        int32_t denom = (x_ac * y_dc_max) >> 7;
        if (denom > 0) {
            ratio[ratio_cnt++] = (nume * 100) / denom;
        }
    }

    if (ratio_cnt > 0) {
        maxim_sort_ascend(ratio, ratio_cnt);
        int mid = ratio_cnt / 2;
        int avg = (ratio_cnt % 2 == 0) ? (ratio[mid - 1] + ratio[mid]) / 2 : ratio[mid];

        if (avg > 2 && avg < 184) {
            *spo2 = (int32_t)uch_spo2_table[avg];
            *spo2_valid = 1;
        } else {
            *spo2 = -999;
            *spo2_valid = 0;
        }
    } else {
        *spo2 = -999;
        *spo2_valid = 0;
    }
}
```

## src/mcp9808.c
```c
#include <zephyr/kernel.h>
#include <zephyr/drivers/i2c.h>
#include "mcp9808.h"

#define MCP9808_ADDR 0x18
#define MCP9808_REG_TEMP 0x05

/* Odczyt temperatury z MCP9808 */
bool mcp9808_read_temp(const struct device *i2c, float *out_temp_c)
{
    uint8_t reg = MCP9808_REG_TEMP;
    uint8_t data[2];
    int ret = i2c_write_read(i2c, MCP9808_ADDR, &reg, 1, data, 2);
    if (ret != 0) {
        return false;
    }

    int16_t raw = ((data[0] & 0x1F) << 8) | data[1];
    if (data[0] & 0x10) {
        raw -= 8192; 
    }

    *out_temp_c = raw * 0.0625f;
    return true;
}
```

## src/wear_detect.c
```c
#include <zephyr/kernel.h>
#include <zephyr/drivers/i2c.h>
//#include <zephyr/sys/printk.h>
#include "wear_detect.h"

#define MCP9808_ADDR 0x18
#define MCP9808_REG_TEMP 0x05

static float last_temp_c = 0.0f;

bool wear_detect_init(const struct device *i2c_temp)
{
    if (!device_is_ready(i2c_temp)) {
        //printk("Wear detect: I2C not ready!\n");
        return false;
    }

    uint8_t reg = 0x07;
    uint8_t id[2];
    if (i2c_write_read(i2c_temp, MCP9808_ADDR, &reg, 1, id, 2) == 0) {
        if (id[0] == 0x04 && id[1] == 0x00) {
            printk("MCP9808 detected OK\n");
            return true;
        }
    }
  //  printk("MCP9808 not responding\n");
    return false;
}
/*  wykrywanie noszenia */
bool wear_detect(const struct device *i2c_temp)
{
    uint8_t reg = MCP9808_REG_TEMP;
    uint8_t data[2];
    int ret = i2c_write_read(i2c_temp, MCP9808_ADDR, &reg, 1, data, 2);

    if (ret != 0) {
        //printk("Wear detect: I2C read error %d\n", ret);
        return false;
    }

    int16_t raw = ((data[0] & 0x1F) << 8) | data[1];
    if (data[0] & 0x10) raw -= 8192; // temp < 0
    last_temp_c = raw * 0.0625f;

    int t_int = (int)last_temp_c;
    int t_frac = (int)((last_temp_c - t_int) * 100);
    if (t_frac < 0) t_frac = -t_frac;


    //printk("Temp: %d.%02d C\n", t_int, t_frac);

    return (last_temp_c > 28.0f);
}
```
